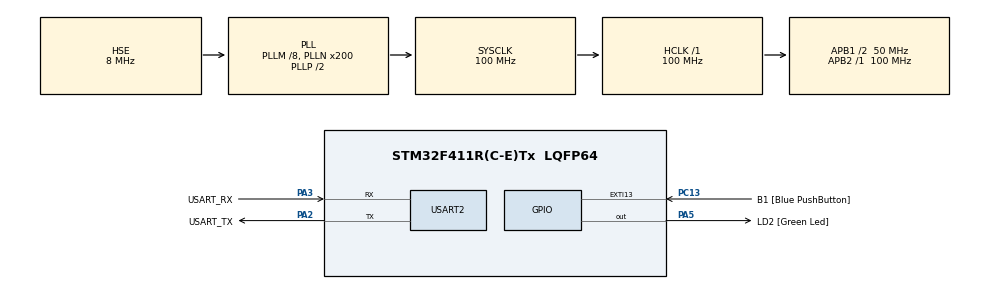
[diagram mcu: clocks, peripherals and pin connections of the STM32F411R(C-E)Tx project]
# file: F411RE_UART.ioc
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Mcu.Family=STM32F4
Mcu.Name=STM32F411R(C-E)Tx
Mcu.Package=LQFP64
NVIC.PriorityGroup=NVIC_PRIORITYGROUP_0
PA13.GPIO_Label=TMS
PA13.Mode=Serial_Wire
PA13.Signal=SYS_JTMS-SWDIO
PA14.GPIO_Label=TCK
PA14.Mode=Serial_Wire
PA14.Signal=SYS_JTCK-SWCLK
PA2.GPIO_Label=USART_TX
PA2.Mode=Asynchronous
PA2.Signal=USART2_TX
PA3.GPIO_Label=USART_RX
PA3.Mode=Asynchronous
PA3.Signal=USART2_RX
PA5.GPIO_Label=LD2 [Green Led]
PA5.Signal=GPIO_Output
PB3.GPIO_Label=SWO
PB3.Signal=SYS_JTDO-SWO
PC13-ANTI_TAMP.GPIO_Label=B1 [Blue PushButton]
PC13-ANTI_TAMP.GPIO_ModeDefaultEXTI=GPIO_MODE_IT_FALLING
PC13-ANTI_TAMP.Signal=GPXTI13
PC14-OSC32_IN.Signal=RCC_OSC32_IN
PC15-OSC32_OUT.Signal=RCC_OSC32_OUT
PH0\ -\ OSC_IN.Mode=HSE-External-Clock-Source
PH0\ -\ OSC_IN.Signal=RCC_OSC_IN
PH1\ -\ OSC_OUT.Mode=HSE-External-Clock-Source
PH1\ -\ OSC_OUT.Signal=RCC_OSC_OUT
ProjectManager.HeapSize=0x200
ProjectManager.StackSize=0x400
ProjectManager.TargetToolchain=STM32CubeIDE
RCC.48MHZClocksFreq_Value=50000000
RCC.AHBFreq_Value=100000000
RCC.APB1CLKDivider=RCC_HCLK_DIV2
RCC.APB1Freq_Value=50000000
RCC.APB1TimFreq_Value=100000000
RCC.APB2Freq_Value=100000000
RCC.APB2TimFreq_Value=100000000
RCC.CortexFreq_Value=100000000
RCC.FLatency-AdvancedSettings=FLASH_LATENCY_3
RCC.HCLKFreq_Value=100000000
RCC.HSE_VALUE=8000000
RCC.HSI_VALUE=16000000
RCC.LSE_VALUE=32768
RCC.PLLM=8
RCC.PLLN=200
RCC.PLLSourceVirtual=RCC_PLLSOURCE_HSE
RCC.SYSCLKFreq_VALUE=100000000
RCC.SYSCLKSource=RCC_SYSCLKSOURCE_PLLCLK
RCC.VCOOutputFreq_Value=200000000
USART2.VirtualMode=VM_ASYNC
board=NUCLEO-F411RE

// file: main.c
/* USER CODE BEGIN Header */
/**
  ******************************************************************************
  * @file           : F411RE/phase0_alive/main.c
  * @brief          : 1. 전원이 깨끗한가 (멀티미터)
  *                   2. GND가 연속인가 (연속성 시험)
  *                   3. MCU가 살아서 코드를 도는가 (LED + UART)
  *                 LED 점멸: "코어가 살아있다"
  *                 UART 정상 출력: "클럭 트리 설정이 실제로 맞다"
  ******************************************************************************
  * @attention
  *
  * Copyright (c) 2026 STMicroelectronics.
  * All rights reserved.
  *
  * This software is licensed under terms that can be found in the LICENSE file
  * in the root directory of this software component.
  * If no LICENSE file comes with this software, it is provided AS-IS.
  *
  ******************************************************************************
  */
/* USER CODE END Header */
#include "main.h"

/* USER CODE BEGIN Includes */
#include <stdio.h>
/* USER CODE END Includes */

UART_HandleTypeDef huart2;

void SystemClock_Config(void);
static void MX_GPIO_Init(void);
static void MX_USART2_UART_Init(void);

int main(void)
{

  /* USER CODE BEGIN 1 */
  // 7/30 main 초기화 순서 복습
  //
  // 1. HAL_Init();
  // 2. SystemClock_Config();
  // 3. MX_GPIO_Init();
  // 4. MX_USART2_UART_Init();
  /* USER CODE END 1 */

  /* MCU Configuration--------------------------------------------------------*/

  /* Reset of all peripherals, Initializes the Flash interface and the Systick. */
  HAL_Init();

  /* Configure the system clock */
  SystemClock_Config();

  /* USER CODE BEGIN SysInit */
  // 7/30 클럭 상향 전에 전압을 먼저 올려야 함 (VOS Scale1 = 100MHz 조건)
  //   __HAL_RCC_PWR_CLK_ENABLE();          PWR 레지스터 접근용 클럭
  //   __HAL_PWR_VOLTAGESCALING_CONFIG(PWR_REGULATOR_VOLTAGE_SCALE1);
  /* USER CODE END SysInit */

  /* Initialize all configured peripherals */
  MX_GPIO_Init();
  MX_USART2_UART_Init();
  /* USER CODE BEGIN 2 */
  uint32_t last_tick = 0;
  uint8_t led_state = 0;
  /* USER CODE END 2 */

  /* Infinite loop */
  while (1)
  {

    /* USER CODE BEGIN 3 */
	  uint32_t now = HAL_GetTick();
	  if(now - last_tick >= 500) { // HAL_Delay(500) -> 이건 500ms 동안 CPU를 붙잡고 있음. Delay로 막혀 있으면 RX 버퍼가 오버런됨
		  last_tick = now;           // if 조건 하나가 LED와 UART를 동시에 지배
		  led_state = !led_state; // 500ms on / 500ms off = 1Hz 점멸, on->off->on 토글 2번 필요 1000ms = 1Hz
		  HAL_GPIO_WritePin(LD2_GPIO_Port, LD2_Pin, led_state);

		  char msg[48];
		  int len = snprintf(msg, sizeof(msg), "[F411RE] alive, t=%lums\r\n", now);
      // printf는 stdout으로 나가므로 newlib의 _write() retarget이 필요
      // snprintf는 버퍼에만 쓰므로 retarget 없이 바로 넘길 수 있고, 힙을 안 씀
      // 그런데 MISRA C에선 <stdio.h>의 표준 입출력 함수 사용을 금지함
      // snprintf까지 포함.
		  HAL_UART_Transmit(&huart2, (uint8_t*)msg, len, 100);
      // 이건 500ms마다 한 번. 초당 2번 -> 2Hz
	  }
  }
  /* USER CODE END 3 */
}

void SystemClock_Config(void)
{
  RCC_OscInitTypeDef RCC_OscInitStruct = {0};
  RCC_ClkInitTypeDef RCC_ClkInitStruct = {0};

  /** Configure the main internal regulator output voltage
  */
  __HAL_RCC_PWR_CLK_ENABLE();
  __HAL_PWR_VOLTAGESCALING_CONFIG(PWR_REGULATOR_VOLTAGE_SCALE1);

  /** Initializes the RCC Oscillators according to the specified parameters
  * in the RCC_OscInitTypeDef structure.
  */
  RCC_OscInitStruct.OscillatorType = RCC_OSCILLATORTYPE_HSE;
  RCC_OscInitStruct.HSEState = RCC_HSE_BYPASS;
  RCC_OscInitStruct.PLL.PLLState = RCC_PLL_ON;
  RCC_OscInitStruct.PLL.PLLSource = RCC_PLLSOURCE_HSE;
  RCC_OscInitStruct.PLL.PLLM = 8;
  RCC_OscInitStruct.PLL.PLLN = 200;
  RCC_OscInitStruct.PLL.PLLP = RCC_PLLP_DIV2;
  RCC_OscInitStruct.PLL.PLLQ = 4;
  if (HAL_RCC_OscConfig(&RCC_OscInitStruct) != HAL_OK)
  {
    Error_Handler();
  }

  /** Initializes the CPU, AHB and APB buses clocks
  */
  RCC_ClkInitStruct.ClockType = RCC_CLOCKTYPE_HCLK|RCC_CLOCKTYPE_SYSCLK
                              |RCC_CLOCKTYPE_PCLK1|RCC_CLOCKTYPE_PCLK2;
  RCC_ClkInitStruct.SYSCLKSource = RCC_SYSCLKSOURCE_PLLCLK;
  RCC_ClkInitStruct.AHBCLKDivider = RCC_SYSCLK_DIV1;
  RCC_ClkInitStruct.APB1CLKDivider = RCC_HCLK_DIV2;
  RCC_ClkInitStruct.APB2CLKDivider = RCC_HCLK_DIV1;

  if (HAL_RCC_ClockConfig(&RCC_ClkInitStruct, FLASH_LATENCY_3) != HAL_OK)
  {
    Error_Handler();
  }
}

static void MX_USART2_UART_Init(void)
{

  huart2.Instance = USART2;
  huart2.Init.BaudRate = 115200;
  huart2.Init.WordLength = UART_WORDLENGTH_8B;
  huart2.Init.StopBits = UART_STOPBITS_1;
  huart2.Init.Parity = UART_PARITY_NONE;
  huart2.Init.Mode = UART_MODE_TX_RX;
  huart2.Init.HwFlowCtl = UART_HWCONTROL_NONE;
  huart2.Init.OverSampling = UART_OVERSAMPLING_16;
  if (HAL_UART_Init(&huart2) != HAL_OK)
  {
    Error_Handler();
  }

}

static void MX_GPIO_Init(void)
{
  GPIO_InitTypeDef GPIO_InitStruct = {0};

  /* GPIO Ports Clock Enable */
  __HAL_RCC_GPIOC_CLK_ENABLE();
  __HAL_RCC_GPIOH_CLK_ENABLE();
  __HAL_RCC_GPIOA_CLK_ENABLE();
  __HAL_RCC_GPIOB_CLK_ENABLE();

  /*Configure GPIO pin Output Level */
  HAL_GPIO_WritePin(LD2_GPIO_Port, LD2_Pin, GPIO_PIN_RESET);

  /*Configure GPIO pin : B1_Pin */
  GPIO_InitStruct.Pin = B1_Pin;
  GPIO_InitStruct.Mode = GPIO_MODE_IT_FALLING;
  GPIO_InitStruct.Pull = GPIO_NOPULL;
  HAL_GPIO_Init(B1_GPIO_Port, &GPIO_InitStruct);

  /*Configure GPIO pin : LD2_Pin */
  GPIO_InitStruct.Pin = LD2_Pin;
  GPIO_InitStruct.Mode = GPIO_MODE_OUTPUT_PP;
  GPIO_InitStruct.Pull = GPIO_NOPULL;
  GPIO_InitStruct.Speed = GPIO_SPEED_FREQ_LOW;
  HAL_GPIO_Init(LD2_GPIO_Port, &GPIO_InitStruct);

}

void Error_Handler(void)
{
  /* USER CODE BEGIN Error_Handler_Debug */
  // Error_Handler() - 기본 구현의 의도는 두 가지
  // 1. fail-fast : 고장 상태에서 시스템이 어중간하게 계속 돌지 않게 함
  // 2. 디버깅 편의: 디버거를 붙이면 PC가 여기 멈춰 있으니, 콜스택으로 어느 HAL_xxx_Init()이 실패했는지 즉시 역추적 가능
  /* User can add his own implementation to report the HAL error return state */
  __disable_irq();
  while (1)
  {
  }
  /* USER CODE END Error_Handler_Debug */
}
